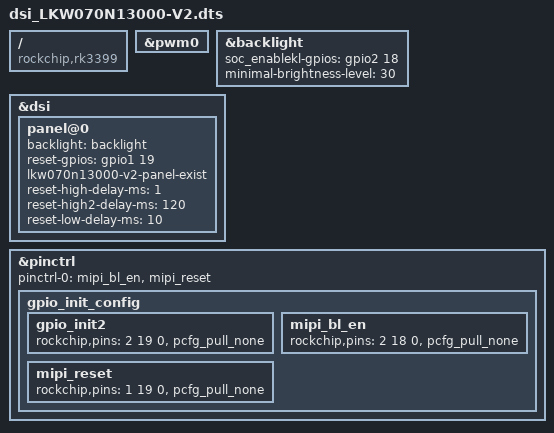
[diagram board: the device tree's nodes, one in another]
/dts-v1/;
/plugin/;
/ {
	compatible = "rockchip,rk3399";

	fragment@0 {
		target = <&pwm0>;
		__overlay__ {
			status = "okay";
		};
	};
	fragment@1 {
		target = <&backlight>;
		__overlay__ {
			status = "okay";
			soc_enablekl-gpios = <&gpio2 18 0>;
			minimal-brightness-level = <30>;
		};
	};
	fragment@2 {
		target = <&dsi>;
		__overlay__ {
			status = "okay";
			panel@0 {
				backlight = <&backlight>;
				reset-gpios = <&gpio1 19 0>;
				lkw070n13000-v2-panel-exist;
				reset-high-delay-ms = <1>;
				reset-high2-delay-ms = <120>;
				reset-low-delay-ms = <10>;
			};
		};
	};
	fragment@3 {
		target = <&pinctrl>;
		__overlay__ {
			pinctrl-0 = <&gpio_init2>;
			gpio_init_config {
				gpio_init2: gpio_init2 {
					rockchip,pins =
						<2 19 0 &pcfg_pull_none>;
				};
			};
		};
	};
	fragment@4 {
		target = <&pinctrl>;
		__overlay__ {
			pinctrl-0 = <&mipi_bl_en &mipi_reset>;
			gpio_init_config {
				mipi_bl_en: mipi_bl_en {
					rockchip,pins =
						<2 18 0 &pcfg_pull_none>;
				};
				mipi_reset: mipi_reset {
					rockchip,pins =
						<1 19 0 &pcfg_pull_none>;
				};
			};
		};
	};
};
